VERSION ""

NS_ :

BS_:

BU_:

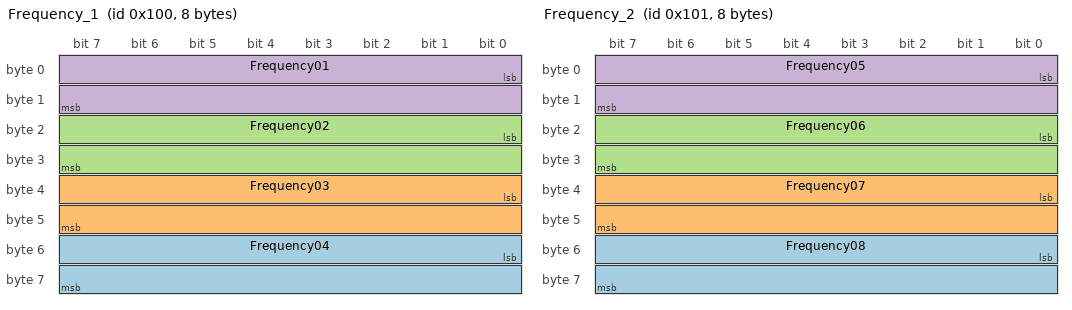
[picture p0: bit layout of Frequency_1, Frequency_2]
BO_ 256 Frequency_1: 8 Vector__XXX
 SG_ Frequency04 : 48|16@1- (1,0) [0|0] "degC" Vector__XXX
 SG_ Frequency03 : 32|16@1- (1,0) [0|0] "degC" Vector__XXX
 SG_ Frequency02 : 16|16@1- (1,0) [0|0] "degC" Vector__XXX
 SG_ Frequency01 : 0|16@1- (1,0) [0|0] "degC" Vector__XXX

BO_ 257 Frequency_2: 8 Vector__XXX
 SG_ Frequency08 : 48|16@1- (1,0) [0|0] "degC" Vector__XXX
 SG_ Frequency07 : 32|16@1- (1,0) [0|0] "degC" Vector__XXX
 SG_ Frequency06 : 16|16@1- (1,0) [0|0] "degC" Vector__XXX
 SG_ Frequency05 : 0|16@1- (1,0) [0|0] "degC" Vector__XXX

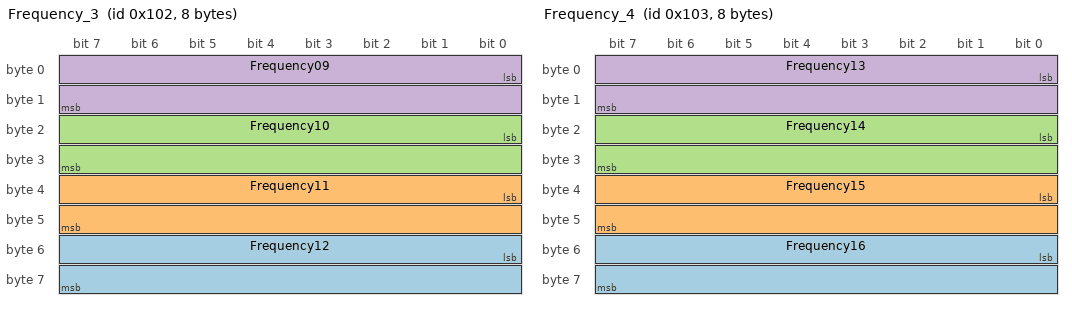
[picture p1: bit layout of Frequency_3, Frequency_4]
BO_ 258 Frequency_3: 8 Vector__XXX
 SG_ Frequency12 : 48|16@1- (1,0) [0|0] "degC" Vector__XXX
 SG_ Frequency11 : 32|16@1- (1,0) [0|0] "degC" Vector__XXX
 SG_ Frequency10 : 16|16@1- (1,0) [0|0] "degC" Vector__XXX
 SG_ Frequency09 : 0|16@1- (1,0) [0|0] "degC" Vector__XXX

BO_ 259 Frequency_4: 8 Vector__XXX
 SG_ Frequency16 : 48|16@1- (1,0) [0|0] "degC" Vector__XXX
 SG_ Frequency15 : 32|16@1- (1,0) [0|0] "degC" Vector__XXX
 SG_ Frequency14 : 16|16@1- (1,0) [0|0] "degC" Vector__XXX
 SG_ Frequency13 : 0|16@1- (1,0) [0|0] "degC" Vector__XXX

BA_DEF_  "BusType" STRING ;
BA_DEF_DEF_  "BusType" "CAN";
